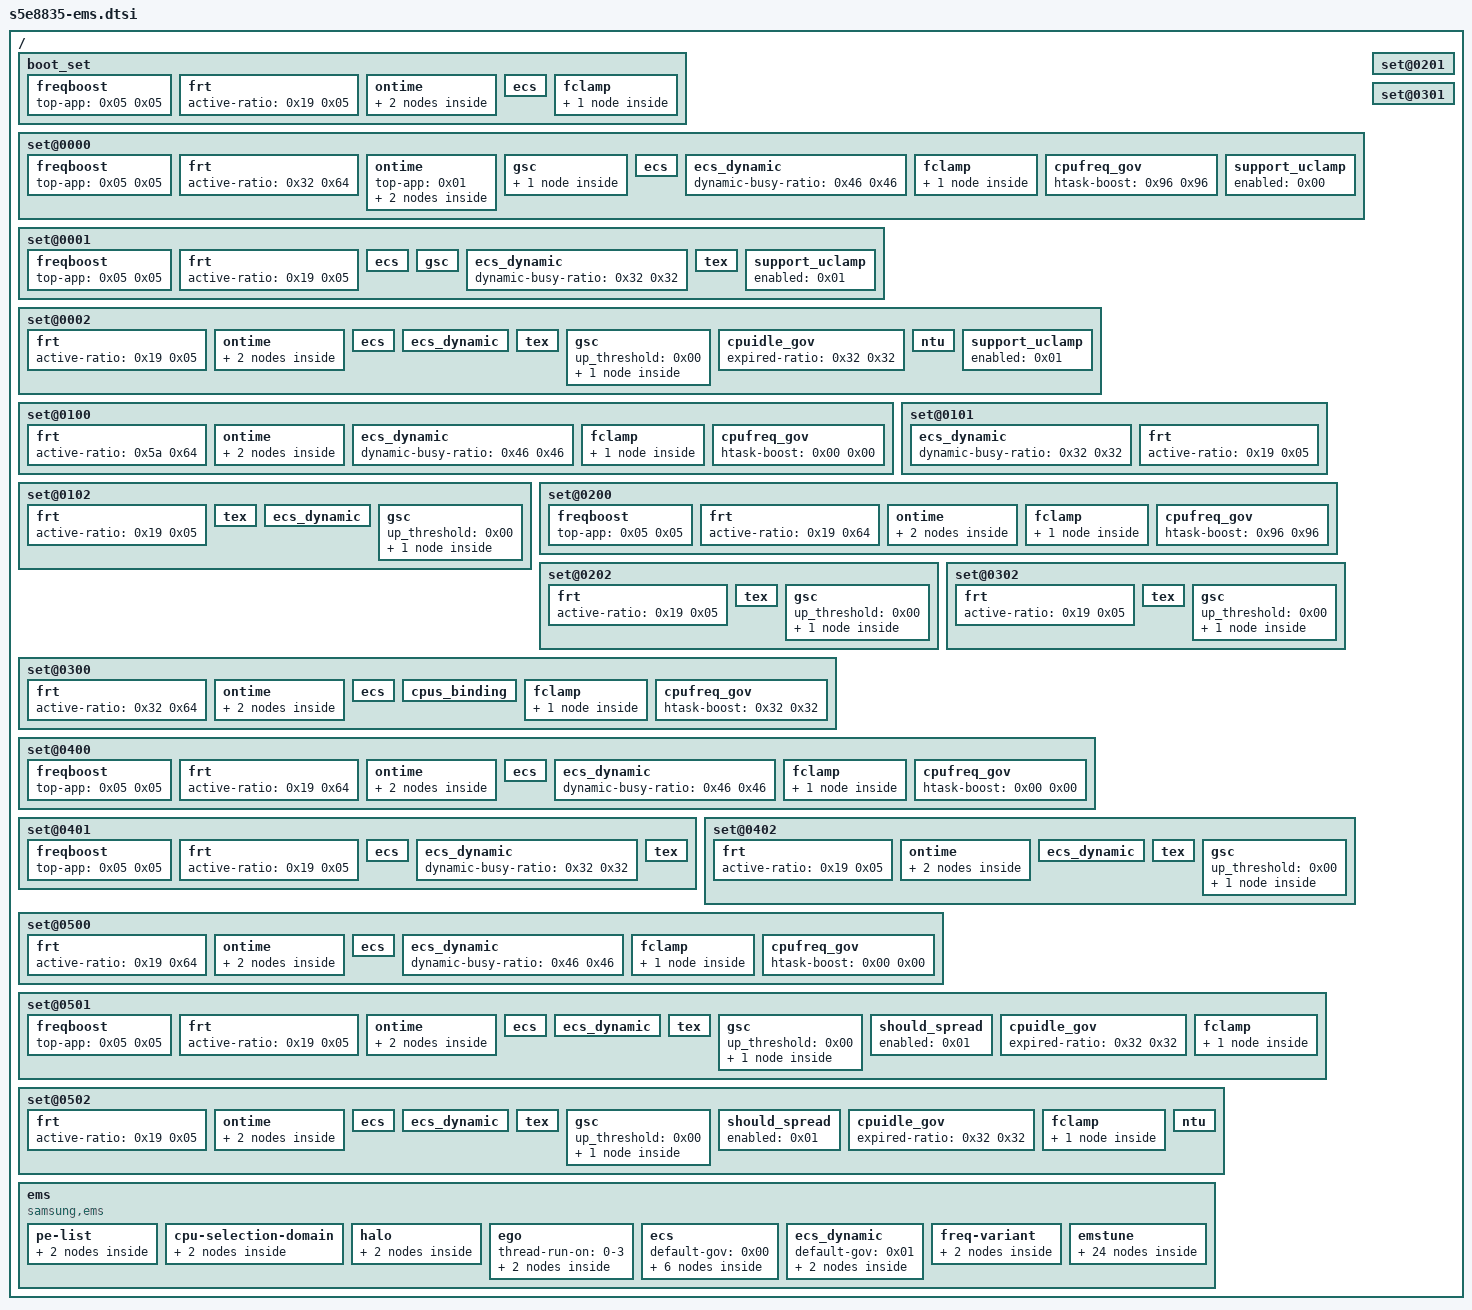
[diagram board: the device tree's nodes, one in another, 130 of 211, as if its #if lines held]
#include <linux/kconfig.h>

/{
	boot_set {
		phandle = <0x17>;

		freqboost {
			top-app = <0x05 0x05>;
		};

		frt {
			active-ratio = <0x19 0x05>;
		};

		ontime {
			foreground = <0x01>;
			top-app = <0x01>;

			domain0 {
				cpus = "0-3";
				lower-boundary = <0x00>;
				upper-boundary = <0x24>;
			};

			domain1 {
				cpus = "4-7";
				lower-boundary = <0x06>;
				upper-boundary = <0x64>;
			};
		};

		ecs {
		};

		fclamp {

			monitor-group {
				top-app = <0x01>;
			};
		};
	};

	set@0000 {
		phandle = <0x18>;

		freqboost {
			top-app = <0x05 0x05>;
		};

		frt {
			active-ratio = <0x32 0x64>;
		};

		ontime {
			top-app = <0x01>;

			domain0 {
				cpus = "0-3";
				lower-boundary = <0x00>;
				upper-boundary = <0x24>;
			};

			domain1 {
				cpus = "4-7";
				lower-boundary = <0x06>;
				upper-boundary = <0x64>;
			};
		};

		gsc {
			up_threshold = <0x64>;
			down_threshold = <0x32>;

			monitor-group {
				top-app = <0x01>;
			};
		};

		ecs {
		};

		ecs_dynamic {
			dynamic-busy-ratio = <0x46 0x46>;
		};

		fclamp {

			monitor-group {
				top-app = <0x01>;
			};
		};

		cpufreq_gov {
			htask-boost = <0x96 0x96>;
		};

		support_uclamp {
			enabled = <0x00>;
		};
	};

	set@0001 {
		phandle = <0x19>;

		freqboost {
			top-app = <0x05 0x05>;
		};

		frt {
			active-ratio = <0x19 0x05>;
		};

		ecs {
		};

		gsc {
		};

		ecs_dynamic {
			dynamic-busy-ratio = <0x32 0x32>;
		};

		tex {
			top-app = <0x01>;
			foreground = <0x01>;
			prio = <0x77>;
		};

		support_uclamp {
			enabled = <0x01>;
		};
	};

	set@0002 {
		phandle = <0x1a>;

		frt {
			active-ratio = <0x19 0x05>;
		};

		ontime {

			domain0 {
				cpus = "0-3";
				lower-boundary = <0x00>;
				upper-boundary = <0x15>;
			};

			domain1 {
				cpus = "4-7";
				lower-boundary = <0x08>;
				upper-boundary = <0x42>;
			};
		};

		ecs {
		};

		ecs_dynamic {
		};

		tex {
			top-app = <0x01>;
			prio = <0x6e>;
		};

		gsc {
			up_threshold = <0x00>;

			monitor-group {
				top-app = <0x01>;
				foreground = <0x01>;
			};
		};

		cpuidle_gov {
			expired-ratio = <0x32 0x32>;
		};

		ntu {
			root = <0x00>;
			foreground = <0x00>;
			background = <0x00>;
			top-app = <0x00>;
			rt = <0x00>;
			system = <0x00>;
			system-background = <0x00>;
			nnapi-hal = <0x00>;
			camera-daemon = <0x00>;
		};

		support_uclamp {
			enabled = <0x01>;
		};
	};

	set@0100 {
		phandle = <0x1b>;

		frt {
			active-ratio = <0x5a 0x64>;
		};

		ontime {
			foreground = <0x01>;
			top-app = <0x01>;

			domain0 {
				cpus = "0-3";
				lower-boundary = <0x00>;
				upper-boundary = <0x2a>;
			};

			domain1 {
				cpus = "4-7";
				lower-boundary = <0x0a>;
				upper-boundary = <0x64>;
			};
		};

		ecs_dynamic {
			dynamic-busy-ratio = <0x46 0x46>;
		};

		fclamp {

			monitor-group {
				top-app = <0x01>;
			};
		};

		cpufreq_gov {
			htask-boost = <0x00 0x00>;
		};
	};

	set@0101 {
		phandle = <0x1c>;

		ecs_dynamic {
			dynamic-busy-ratio = <0x32 0x32>;
		};

		frt {
			active-ratio = <0x19 0x05>;
		};
	};

	set@0102 {
		phandle = <0x1d>;

		frt {
			active-ratio = <0x19 0x05>;
		};

		tex {
			top-app = <0x01>;
			prio = <0x6e>;
		};

		ecs_dynamic {
		};

		gsc {
			up_threshold = <0x00>;

			monitor-group {
				top-app = <0x01>;
				foreground = <0x01>;
			};
		};
	};

	set@0200 {
		phandle = <0x1e>;

		freqboost {
			top-app = <0x05 0x05>;
		};

		frt {
			active-ratio = <0x19 0x64>;
		};

		ontime {
			foreground = <0x01>;
			top-app = <0x01>;

			domain0 {
				cpus = "0-3";
				lower-boundary = <0x00>;
				upper-boundary = <0x08>;
			};

			domain1 {
				cpus = "4-7";
				lower-boundary = <0x01>;
				upper-boundary = <0x64>;
			};
		};

		fclamp {

			monitor-group {
				top-app = <0x01>;
			};
		};

		cpufreq_gov {
			htask-boost = <0x96 0x96>;
		};
	};

	set@0201 {
		phandle = <0x1f>;
	};

	set@0202 {
		phandle = <0x20>;

		frt {
			active-ratio = <0x19 0x05>;
		};

		tex {
			top-app = <0x01>;
			prio = <0x6e>;
		};

		gsc {
			up_threshold = <0x00>;

			monitor-group {
				top-app = <0x01>;
				foreground = <0x01>;
			};
		};
	};

	set@0300 {
		phandle = <0x21>;

		frt {
			active-ratio = <0x32 0x64>;
		};

		ontime {
			foreground = <0x01>;
			top-app = <0x01>;

			domain0 {
				cpus = "0-3";
				lower-boundary = <0x00>;
				upper-boundary = <0x1e>;
			};

			domain1 {
				cpus = "4-7";
				lower-boundary = <0x05>;
				upper-boundary = <0x64>;
			};
		};

		ecs {
		};

		cpus_binding {
			target-sched-class = <0x08>;
			background = "0-3";
		};

		fclamp {

			monitor-group {
				top-app = <0x01>;
			};
		};

		cpufreq_gov {
			htask-boost = <0x32 0x32>;
		};
	};

	set@0301 {
		phandle = <0x22>;
	};

	set@0302 {
		phandle = <0x23>;

		frt {
			active-ratio = <0x19 0x05>;
		};

		tex {
			top-app = <0x01>;
			prio = <0x6e>;
		};

		gsc {
			up_threshold = <0x00>;

			monitor-group {
				top-app = <0x01>;
				foreground = <0x01>;
			};
		};
	};

	set@0400 {
		phandle = <0x24>;

		freqboost {
			top-app = <0x05 0x05>;
		};

		frt {
			active-ratio = <0x19 0x64>;
		};

		ontime {
			top-app = <0x01>;
			foreground = <0x01>;

			domain0 {
				cpus = "0-3";
				lower-boundary = <0x00>;
				upper-boundary = <0x3a>;
			};

			domain1 {
				cpus = "4-7";
				lower-boundary = <0x09>;
				upper-boundary = <0x64>;
			};
		};

		ecs {
		};

		ecs_dynamic {
			dynamic-busy-ratio = <0x46 0x46>;
		};

		fclamp {
			max-freq = <0x177000 0x1ec300>;
			max-target-period = <0x04 0x04>;
			max-target-ratio = <0x50 0x50>;

			monitor-group {
				top-app = <0x01>;
				foreground = <0x01>;
			};
		};

		cpufreq_gov {
			htask-boost = <0x00 0x00>;
		};
	};

	set@0401 {
		phandle = <0x25>;

		freqboost {
			top-app = <0x05 0x05>;
		};

		frt {
			active-ratio = <0x19 0x05>;
		};

		ecs {
		};

		ecs_dynamic {
			dynamic-busy-ratio = <0x32 0x32>;
		};

		tex {
			top-app = <0x01>;
			prio = <0x77>;
		};
	};

	set@0402 {
		phandle = <0x26>;

		frt {
			active-ratio = <0x19 0x05>;
		};

		ontime {
			foreground = <0x01>;
			top-app = <0x01>;

			domain0 {
				cpus = "0-3";
				lower-boundary = <0x00>;
				upper-boundary = <0x15>;
			};

			domain1 {
				cpus = "4-7";
				lower-boundary = <0x08>;
				upper-boundary = <0x42>;
			};
		};

		ecs_dynamic {
		};

		tex {
			top-app = <0x01>;
			prio = <0x6e>;
		};

		gsc {
			up_threshold = <0x00>;

			monitor-group {
				top-app = <0x01>;
				foreground = <0x01>;
			};
		};
	};

	set@0500 {
		phandle = <0x27>;

		frt {
			active-ratio = <0x19 0x64>;
		};

		ontime {
			top-app = <0x01>;
			foreground = <0x01>;
			camera-daemon = <0x01>;

			domain0 {
				cpus = "0-3";
				lower-boundary = <0x00>;
				upper-boundary = <0x3c>;
			};

			domain1 {
				cpus = "4-7";
				lower-boundary = <0x1e>;
				upper-boundary = <0x64>;
			};
		};

		ecs {
		};

		ecs_dynamic {
			dynamic-busy-ratio = <0x46 0x46>;
		};

		fclamp {
			min-freq = <0x82208 0x82208>;
			min-target-period = <0x04 0x04>;
			min-target-ratio = <0x14 0x14>;
			max-freq = <0x177000 0x1ec300>;
			max-target-period = <0x04 0x04>;
			max-target-ratio = <0x50 0x50>;

			monitor-group {
				top-app = <0x01>;
				foreground = <0x01>;
				camera-daemon = <0x01>;
			};
		};

		cpufreq_gov {
			htask-boost = <0x00 0x00>;
		};
	};

	set@0501 {
		phandle = <0x28>;

		freqboost {
			top-app = <0x05 0x05>;
		};

		frt {
			active-ratio = <0x19 0x05>;
		};

		ontime {
			top-app = <0x01>;
			camera-daemon = <0x01>;

			domain0 {
				cpus = "0-3";
				lower-boundary = <0x00>;
				upper-boundary = <0x15>;
			};

			domain1 {
				cpus = "4-7";
				lower-boundary = <0x08>;
				upper-boundary = <0x42>;
			};
		};

		ecs {
		};

		ecs_dynamic {
		};

		tex {
			top-app = <0x01>;
			camera-daemon = <0x01>;
			prio = <0x6e>;
		};

		gsc {
			up_threshold = <0x00>;

			monitor-group {
				top-app = <0x01>;
				camera-daemon = <0x01>;
			};
		};

		should_spread {
			enabled = <0x01>;
		};

		cpuidle_gov {
			expired-ratio = <0x32 0x32>;
		};

		fclamp {
			min-freq = <0x177000 0x177000>;
			min-target-period = <0x04 0x04>;
			min-target-ratio = <0x14 0x14>;
			max-freq = <0x1e8c50 0x249f00>;
			max-target-period = <0x04 0x04>;
			max-target-ratio = <0x50 0x50>;

			monitor-group {
				top-app = <0x01>;
				camera-daemon = <0x01>;
			};
		};
	};

	set@0502 {
		phandle = <0x29>;

		frt {
			active-ratio = <0x19 0x05>;
		};

		ontime {
			top-app = <0x01>;
			camera-daemon = <0x01>;

			domain0 {
				cpus = "0-3";
				lower-boundary = <0x00>;
				upper-boundary = <0x15>;
			};

			domain1 {
				cpus = "4-7";
				lower-boundary = <0x08>;
				upper-boundary = <0x42>;
			};
		};

		ecs {
		};

		ecs_dynamic {
		};

		tex {
			top-app = <0x01>;
			camera-daemon = <0x01>;
			prio = <0x6e>;
		};

		gsc {
			up_threshold = <0x00>;

			monitor-group {
				top-app = <0x01>;
				camera-daemon = <0x01>;
			};
		};

		should_spread {
			enabled = <0x01>;
		};

		cpuidle_gov {
			expired-ratio = <0x32 0x32>;
		};

		fclamp {
			min-freq = <0x177000 0x177000>;
			min-target-period = <0x04 0x04>;
			min-target-ratio = <0x14 0x14>;
			max-freq = <0x1e8c50 0x249f00>;
			max-target-period = <0x04 0x04>;
			max-target-ratio = <0x50 0x50>;

			monitor-group {
				top-app = <0x01>;
				camera-daemon = <0x01>;
			};
		};

		ntu {
			root = <0x00>;
			foreground = <0x00>;
			background = <0x00>;
			top-app = <0x00>;
			rt = <0x00>;
			system = <0x00>;
			system-background = <0x00>;
			nnapi-hal = <0x00>;
			camera-daemon = <0x00>;
		};
	};

	ems {
		compatible = "samsung,ems";
		status = "okay";

		pe-list {

			list@0 {
				cpus = "0-3", "4-7";
			};

			list@1 {
				cpus = "4-7", "0-3";
			};
		};

		cpu-selection-domain {

			ananke {
				cpus = "0-3";
			};

			hercules {
				cpus = "4-7";
			};
		};

		halo {

			domain@0 {
				cpus = "0-3";
				expired-ratio = <0x64>;
			};

			domain@1 {
				cpus = "4-7";
				expired-ratio = <0x64>;
			};
		};

		ego {
			thread-run-on = "0-3";

			domain@0 {
				cpus = "0-3";
				ratio = <0x3e8>;
			};

			domain@1 {
				cpus = "4-7";
				ratio = <0x3e8>;
#if IS_ENABLED(CONFIG_SOC_S5E8835_CPU_OC)
				somac_wall = <2500000>;
#else
				somac_wall = <2400000>;
#endif
			};
		};

		ecs {
			default-gov = <0x00>;

			domain0 {
				cpus = "0-3";

				stage0 {
					cpus = "0-1";
				};

				stage1 {
					cpus = "0-3";
				};
			};

			domain1 {
				cpus = "4-7";

				stage0 {
					cpus = "4-5";
					busy-threshold = <0x00>;
				};

				stage1 {
					cpus = "4-7";
				};
			};
		};

		ecs_dynamic {
			default-gov = <0x01>;

			domain0 {
				cpus = "0-3";
				default-cpus = "0-3";
			};

			domain1 {
				cpus = "4-7";
				default-cpus = "4-5";
			};
		};

		freq-variant {

			domain@0 {
				cpus = "0-3";
				table = <0xd2f00 0x5dc 0x148200 0x7d0 0x1a5e00 0xbb8>;
			};

			domain@1 {
				cpus = "4-7";
				table = <0xea600 0x7d0 0x1a5e00 0x9c4 0x249f00 0xfa0>;
			};
		};

		emstune {
			boost-level = <0x02>;
			boot-set = <0x17>;

			mode0 {
				desc = "normal";

				level0 {
					base = <0x18>;
					set = <0x18>;
				};

				level1 {
					base = <0x18>;
					set = <0x19>;
				};

				level2 {
					base = <0x18>;
					set = <0x1a>;
				};
			};

			mode1 {
				desc = "power-scenario";

				level0 {
					base = <0x1b>;
					set = <0x1b>;
				};

				level1 {
					base = <0x1b>;
					set = <0x1c>;
				};

				level2 {
					base = <0x1b>;
					set = <0x1d>;
				};
			};

			mode2 {
				desc = "performance";

				level0 {
					base = <0x1e>;
					set = <0x1e>;
				};

				level1 {
					base = <0x1e>;
					set = <0x1f>;
				};

				level2 {
					base = <0x1e>;
					set = <0x20>;
				};
			};

			mode3 {
				desc = "game";

				level0 {
					base = <0x21>;
					set = <0x21>;
				};

				level1 {
					base = <0x21>;
					set = <0x22>;
				};

				level2 {
					base = <0x21>;
					set = <0x23>;
				};
			};

			mode4 {
				desc = "balance";

				level0 {
					base = <0x24>;
					set = <0x24>;
				};

				level1 {
					base = <0x24>;
					set = <0x25>;
				};

				level2 {
					base = <0x24>;
					set = <0x26>;
				};
			};

			mode5 {
				desc = "camera";

				level0 {
					base = <0x27>;
					set = <0x27>;
				};

				level1 {
					base = <0x27>;
					set = <0x28>;
				};

				level2 {
					base = <0x27>;
					set = <0x29>;
				};
			};
		};
	};
};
